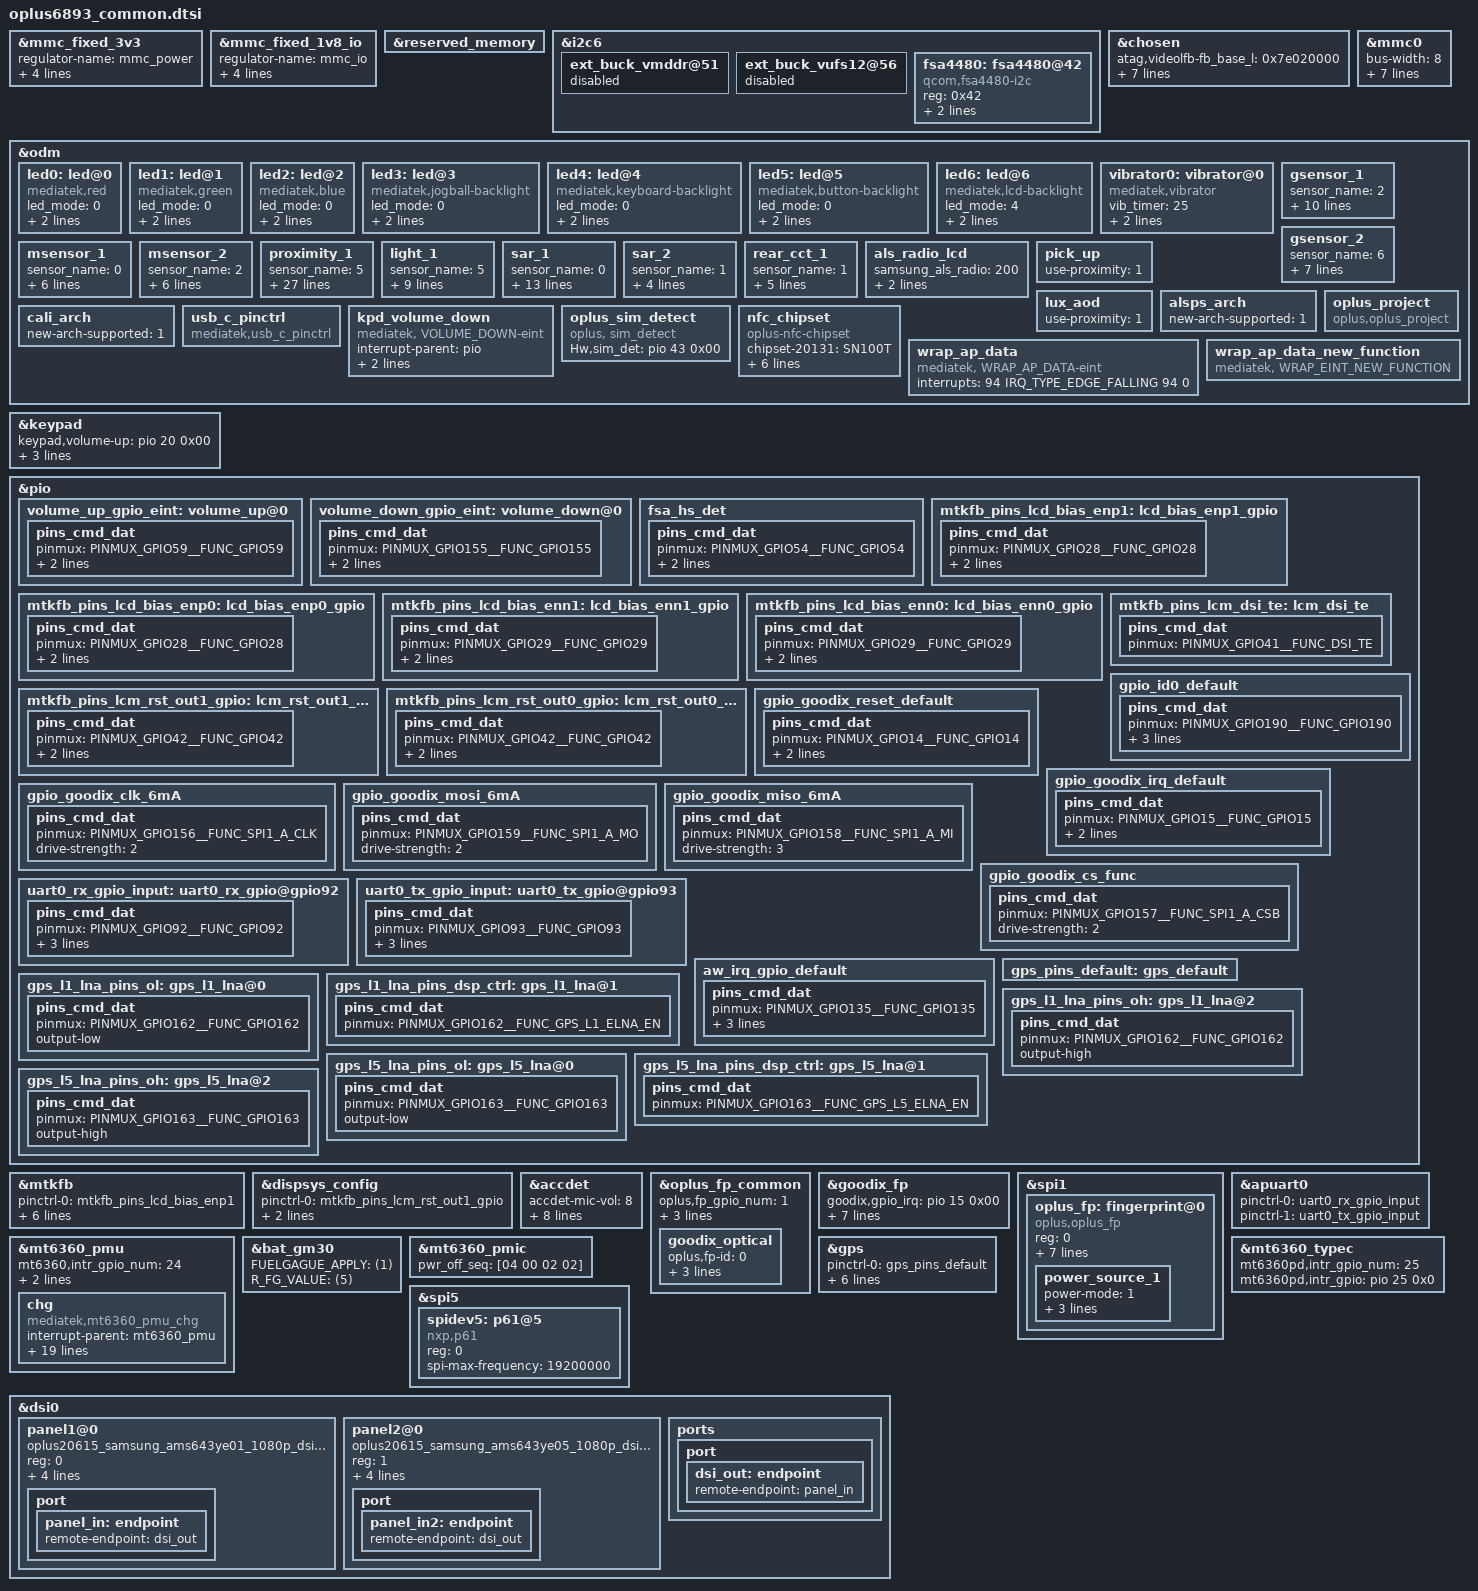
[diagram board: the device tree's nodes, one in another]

&mmc_fixed_3v3 {
	status = "okay";
	regulator-name = "mmc_power";
	regulator-min-microvolt = <3300000>;
	regulator-max-microvolt = <3300000>;
	enable-active-high;
	regulator-always-on;
};

&mmc_fixed_1v8_io {
	status = "okay";
	regulator-name = "mmc_io";
	regulator-min-microvolt = <1800000>;
	regulator-max-microvolt = <1800000>;
	enable-active-high;
	regulator-always-on;
};

&reserved_memory {
};

&i2c6 {

	ext_buck_vmddr@51 {
		status = "disabled";
	};

	ext_buck_vufs12@56 {
		status = "disabled";
	};
 };

/* chosen */
&chosen {

	atag,videolfb-fb_base_l = <0x7e020000>;
	atag,videolfb-fb_base_h = <0x0>;
	atag,videolfb-islcmfound = <1>;
	atag,videolfb-islcm_inited = <0>;
	atag,videolfb-fps= <6000>;
	atag,videolfb-vramSize= <0x1be0000>;
	atag,videolfb-lcmname=
		"nt35595_fhd_dsi_cmd_truly_nt50358_drv";
};

&mmc0 {
	status = "okay";
	/* pinctrl-names = "default", "state_uhs"; */
	/* pinctrl-0 = <&mmc0_pins_default>; */
	/* pinctrl-1 = <&mmc0_pins_uhs>; */
	bus-width = <8>;
	max-frequency = <5000000>;
	cap-mmc-highspeed;
	no-sdio;
	no-sd;
	vmmc-supply = <&mmc_fixed_3v3>;
	vqmmc-supply = <&mmc_fixed_1v8_io>;
	non-removable;
};

&odm {
	led0:led@0 {
		compatible = "mediatek,red";
		led_mode = <0>;
		data = <1>;
		pwm_config = <0 0 0 0 0>;
	};
	led1:led@1 {
		compatible = "mediatek,green";
		led_mode = <0>;
		data = <1>;
		pwm_config = <0 0 0 0 0>;
	};
	led2:led@2 {
		compatible = "mediatek,blue";
		led_mode = <0>;
		data = <1>;
		pwm_config = <0 0 0 0 0>;
	};
	led3:led@3 {
		compatible = "mediatek,jogball-backlight";
		led_mode = <0>;
		data = <1>;
		pwm_config = <0 0 0 0 0>;
	};
	led4:led@4 {
		compatible = "mediatek,keyboard-backlight";
		led_mode = <0>;
		data = <1>;
		pwm_config = <0 0 0 0 0>;
	};
	led5:led@5 {
		compatible = "mediatek,button-backlight";
		led_mode = <0>;
		data = <1>;
		pwm_config = <0 0 0 0 0>;
	};
	led6:led@6 {
		compatible = "mediatek,lcd-backlight";
		led_mode = <4>;
		data = <1>;
		pwm_config = <0 1 0 0 0>;
	};
	vibrator0:vibrator@0 {
		compatible = "mediatek,vibrator";
		vib_timer = <25>;
		vib_limit = <9>;
		vib_vol= <9>;
	};
/* sensor start */
	/*
	enum {
		LIS3DH,
		LSM6DS3,
		BMI160,
		LIS2HH12,
		LSM6DSM,
		BMI2XY,
		LSM6DSO,
	};
	*/
	gsensor_1: gsensor_1 {
		status = "okay";
		sensor_name = <2>;//BMI160
		device_name = "bmi160";
		i2c_num = <2>;
		i2c_addr = <0>;
		direction = <7>;
		eint_num = <3>;
		step_count_7_en = <1>;
		config_miso = <1>;
		correct_y_bias = <1>;
		gyro_cali_version= <2>;
		acc_cali_range= <250 250 250>; //250mg
	};
	gsensor_2: gsensor_2 {
		status = "okay";
		sensor_name = <6>;//LSM6DSO
		device_name = "lsm6dso";
		i2c_num = <2>;
		i2c_addr = <0>;
		direction = <7>;
		eint_num = <3>;
		gyro_cali_version= <2>;
		acc_cali_range= <200 200 200>; //250mg
	};
	/*
	enum {
		AKM09911,
		MMC3530,
		MMC5603,
		MXG4300,
	};
	*/
	msensor_1: msensor_1 {
		status = "okay";
		sensor_name = <0>;//AKM09911
		i2c_num = <0>;
		i2c_addr = <12>;
		direction = <1>;
		eint_num = <0>;
		soft-mag-parameter = <11168 0 285 1 86 1 218 1 9025 0 78 1 263 1 31 0 10658 0>;
	};
	msensor_2: msensor_2 {
		status = "okay";
		sensor_name = <2>;//MMC5603
		i2c_num = <0>;
		i2c_addr = <48>;
		direction = <3>;
		eint_num = <0>;
		soft-mag-parameter = <10343 0 259 0 154 0 259 0 9091 0 49 0 154 0 49 0 10646 0>;
	};
	/*
	enum {
		TMD2725,
		APSD9922,
		STK3335,
		STK3331,
		STK2232,
		TCS3701,
		STK32600,
	};
	*/
	proximity_1: proximity_1 {
		status = "okay";
		sensor_name = <5>;//TCS3701
		i2c_num = <0>;
		i2c_addr = <57>;
		direction = <4>;
		eint_num = <4>;
		low_step = <300>;
		high_step = <400>;
		low_limit = <400>;
		high_limit = <600>;
		dirty_low_step = <100>;
		dirty_high_step = <150>;
		ps_dirty_limit = <1022>;
		ps_ir_limit = <500>;
		ps_adjust_min = <0>;
		ps_adjust_max = <600>;
		sampling_count = <5>;
		step_max = <400>;
		step_min = <110>;
		step_div = <1500>;
		anti_shake_delta = <80>;
		dynamic_cali_max = <1023>;
		raw2offset_radio = <31200>;
		offset_max = <250>;
		offset_range_min = <255>;
		offset_range_max = <255>;
		force_cali_limit = <2000>;
		cali_jitter_limit = <30>;
		cal_offset_margin = <120>;
	};
	light_1: light_1 {
		status = "okay";
		sensor_name = <5>;//TCS3701
		i2c_num = <0>;
		i2c_addr = <57>;
		direction = <4>;
		eint_num = <4>;
		als_ratio = <94>;
		als_buffer_length =<10>;
		lcd_type = <2>;
		use_lb_algo = <1>;
		device_name = "tcs3701";
	};
	/*
	enum {
		SX933x,
		SX933xs,
	};
	*/
	sar_1: sar_1 {
		status = "okay";
		sensor_name = <0>;//SX933x
		i2c_num = <0>;
		i2c_addr = <40>;
		direction = <4>;
		eint_num = <13>;
		channel_num = <2>;
		channel_0_min = <0>;
		channel_0_max = <70000>;
		channel_1_min = <0>;
		channel_1_max = <70000>;
		channel_2_min = <0>;
		channel_2_max = <70000>;
		channel_3_min = <0>;
		channel_3_max = <70000>;
	};

	sar_2: sar_2 {
		status = "okay";
		sensor_name = <1>;//SX933xs
		i2c_num = <0>;
		i2c_addr = <44>;
		direction = <4>;
		eint_num = <13>;
	};

	/*
	enum {
		STK37600,
		MN29005,
		TCS3408,
	};
	*/
	rear_cct_1: rear_cct_1 {
		status = "okay";
		sensor_name = <1>;//MN29005
		i2c_num = <1>;
		i2c_addr = <0x49>;
		direction = <0>;
		eint_num = <0>;
		available_sensor = <0>; // bit 0: rear als, bit 1: rear cct, bit 2: rear flicker
	};

	als_radio_lcd:als_radio_lcd {
		status = "okay";
		samsung_als_radio = <200>;
		boe_als_radio = <150>;
		tianma_als_radio = <150>;
	};
	pick_up: pick_up {
		status = "okay";
		use-proximity = <1>;
	};
	lux_aod: lux_aod {
		status = "okay";
		use-proximity = <1>;
	};
	alsps_arch: alsps_arch {
		status = "okay";
		new-arch-supported = <1>;
	};
	cali_arch: cali_arch {
		status = "okay";
		new-arch-supported = <1>;
	};
/* sensor end */
	usb_c_pinctrl:usb_c_pinctrl {
		compatible = "mediatek,usb_c_pinctrl";
	};
/*OPLUS_FEATURE_TP_BASIC oplus project start */
	oplus_project:oplus_project {
		compatible = "oplus,oplus_project";
	};
/*endif*/
//#ifdef OPLUS_FEATURE_TP_BASIC
        kpd_volume_down:kpd_volume_down {
                compatible = "mediatek, VOLUME_DOWN-eint";
                interrupt-parent = <&pio>;
                interrupts = <155 IRQ_TYPE_EDGE_FALLING 155 0>;
                debounce = <32000>;
                status = "okay";
        };

//#endif OPLUS_FEATURE_TP_BASIC

//#ifdef OPLUS_FEATURE_TP_BASIC
    oplus_sim_detect {
        compatible = "oplus, sim_detect";
        Hw,sim_det = <&pio 43 0x00>;
    };
//#endif /* OPLUS_FEATURE_TP_BASIC */

    nfc_chipset:nfc_chipset {
        compatible = "oplus-nfc-chipset";
        chipset-20131 = "SN100T";
        chipset-20133 = "SN100T";
        chipset-20255 = "SN100T";
        chipset-20615 = "SN100T";
        chipset-20817 = "SN100T";
        chipset-20827 = "SN100T";
        chipset-20831 = "SN100T";
    };
//#endif /* OPLUS_FEATURE_NFC_CONSOFT */

};
//#ifdef OPLUS_FEATURE_TP_BASIC
&keypad {
        keypad,volume-up        = <&pio 20 0x00>;
        keypad,volume-down      = <&pio 155 0x00>;
        pinctrl-names = "volume_up_as_int", "volume_down_as_int";
        pinctrl-0 = <&volume_up_gpio_eint>;
        pinctrl-1 = <&volume_down_gpio_eint>;
        status = "okay";
};

&pio {
        volume_up_gpio_eint:volume_up@0{
                pins_cmd_dat {
                        pinmux = <PINMUX_GPIO59__FUNC_GPIO59>;
                        slew-rate = <0>;  /*direction 0:in, 1:out*/
                        input-enable;
                };
        };

        volume_down_gpio_eint:volume_down@0{
                pins_cmd_dat {
                        pinmux = <PINMUX_GPIO155__FUNC_GPIO155>;
                        slew-rate = <0>;  /*direction 0:in, 1:out*/
                        input-enable;
                };
        };
};
//#endif OPLUS_FEATURE_TP_BASIC

//#ifdef OPLUS_ARCH_EXTENDS
&i2c6 {
	fsa4480: fsa4480@42 {
		compatible = "qcom,fsa4480-i2c";
		reg = <0x42>;
		pinctrl-names = "default";
		pinctrl-0 = <&fsa_hs_det>;
		fsa4480,hs-det-gpio = <&pio 54 0>;
	};
};

&pio {
	fsa_hs_det: fsa_hs_det {
		pins_cmd_dat {
			pinmux = <PINMUX_GPIO54__FUNC_GPIO54>;
			slew-rate = <1>;  /*direction 0:in, 1:out*/
			output-high;
		};
	};
	/*
	aud_gpio_i2s0_on: aud_gpio_i2s0_on {
		pins_cmd1_dat {
			pinmux = <PINMUX_GPIO34__FUNC_I2S3_DI>;
		};
	};*/
};
//#endif /*OPLUS_ARCH_EXTENDS*/

/* DISPSYS GPIO standardization */
&pio {
	mtkfb_pins_lcd_bias_enp1: lcd_bias_enp1_gpio {
		pins_cmd_dat {
			pinmux = <PINMUX_GPIO28__FUNC_GPIO28>;
			slew-rate = <1>;
			output-high;
		};
	};

	mtkfb_pins_lcd_bias_enp0: lcd_bias_enp0_gpio {
		pins_cmd_dat {
			pinmux = <PINMUX_GPIO28__FUNC_GPIO28>;
			slew-rate = <1>;
			output-low;
		};
	};

	mtkfb_pins_lcd_bias_enn1: lcd_bias_enn1_gpio {
		pins_cmd_dat {
			pinmux = <PINMUX_GPIO29__FUNC_GPIO29>;
			slew-rate = <1>;
			output-high;
		};
	};

	mtkfb_pins_lcd_bias_enn0: lcd_bias_enn0_gpio {
		pins_cmd_dat {
			pinmux = <PINMUX_GPIO29__FUNC_GPIO29>;
			slew-rate = <1>;
			output-low;
		};
	};

	mtkfb_pins_lcm_rst_out1_gpio: lcm_rst_out1_gpio {
		pins_cmd_dat {
			pinmux = <PINMUX_GPIO42__FUNC_GPIO42>;
			slew-rate = <1>;
			output-high;
		};
	};

	mtkfb_pins_lcm_rst_out0_gpio: lcm_rst_out0_gpio {
		pins_cmd_dat {
			pinmux = <PINMUX_GPIO42__FUNC_GPIO42>;
			slew-rate = <1>;
			output-low;
		};
	};

	mtkfb_pins_lcm_dsi_te: lcm_dsi_te {
		pins_cmd_dat {
			pinmux = <PINMUX_GPIO41__FUNC_DSI_TE>;
		};
	};
};

&mtkfb {
	pinctrl-names = "lcd_bias_enp1_gpio", "lcd_bias_enp0_gpio",
		"lcd_bias_enn1_gpio", "lcd_bias_enn0_gpio",
		"lcm_rst_out1_gpio", "lcm_rst_out0_gpio",
		"mode_te_te";
	pinctrl-0 = <&mtkfb_pins_lcd_bias_enp1>;
	pinctrl-1 = <&mtkfb_pins_lcd_bias_enp0>;
	pinctrl-2 = <&mtkfb_pins_lcd_bias_enn1>;
	pinctrl-3 = <&mtkfb_pins_lcd_bias_enn0>;
	pinctrl-4 = <&mtkfb_pins_lcm_rst_out1_gpio>;
	pinctrl-5 = <&mtkfb_pins_lcm_rst_out0_gpio>;
	pinctrl-6 = <&mtkfb_pins_lcm_dsi_te>;
	status = "okay";
};

&dispsys_config {
	pinctrl-names =
		"lcm_rst_out1_gpio", "lcm_rst_out0_gpio",
		"mode_te_te";
	pinctrl-0 = <&mtkfb_pins_lcm_rst_out1_gpio>;
	pinctrl-1 = <&mtkfb_pins_lcm_rst_out0_gpio>;
	pinctrl-2 = <&mtkfb_pins_lcm_dsi_te>;
	status = "okay";
};
/* DISPSYS GPIO standardization end */

/* accdet start */
&accdet {
	/* accdet micbias voltage: 0x09:2.85v 0x08:2.8v 0x07,
	 * 2.7v;0x05,2.5v;0x02,1.9v
	 */
	accdet-mic-vol = <8>;
	/* accdet pwm_width, pwm_thresh, fall_delay, rise_delay
	 * debounce0, debounce1, debounce3, debounce4
	 * eint pwm_width, eint pwm_thresh
	 * eint deb(debounce0, debounce1, debounce2, debounce3), inv_debounce
	 */
	headset-mode-setting = <0x500 0x500 1 0x1f0
				0x800 0x800 0x20 0x44
				0x4 0x1
				0x5 0x3 0x3 0x5 0xe>;
	accdet-plugout-debounce = <1>;
	/*1:ACC mode, 2:low cost without in bias, 6:low cost with in bias*/
	accdet-mic-mode = <2>;
	/*0--MD_MAX--UP_MAX--DW_MAX*/
	headset-three-key-threshold = <0 82 170 306>;
	headset-three-key-threshold-CDD = <0 121 192 600>;
	/*0--MD_MAX--VOICE_MAX--UP_MAX--DW_MAX*/
	headset-four-key-threshold = <0 58 121 192 400>;

	/* select VTH to 2v and 500k, use internal resitance */
	eint_use_ext_res = <0>;
	status = "okay";
};
/* accdet end */

/* IRTX GPIO Start */
/*
&irtx_pwm {
	pinctrl-names = "irtx_gpio_led_default", "irtx_gpio_led_set";
	pinctrl-0 = <&irtx_gpio_led_default>;
	pinctrl-1 = <&irtx_gpio_led_set>;
	status = "okay";
};
*/
&pio {
	/* IRTX GPIO Settings -Start */
	/* default: GPIO0, output, high */
	/*
	irtx_gpio_led_default:irtx_gpio_led_def@gpio127 {
		pins_cmd_dat {
			pinmux = <PINMUX_GPIO127__FUNC_GPIO127>;
			slew-rate = <1>;
			bias-disable;
			output-low;
			input-schmitt-enable = <0>;
		};
	};

	irtx_gpio_led_set:irtx_gpio_led_set@gpio127 {
		pins_cmd_dat {
			pinmux = <PINMUX_GPIO127__FUNC_PWM_3>;
			slew-rate = <1>;
			output-high;
		};
	};*/
}; /* IRTX GPIO Settings -End */

/* FINGERPRINT start */
&oplus_fp_common {
    oplus,fp_gpio_num = <1>;
    oplus,fp_gpio = <190>;
    oplus,fp_gpio_id = <&pio 190 0x0>;
    pinctrl-names = "default";
    pinctrl-0 = <&gpio_id0_default>;
    goodix_optical {
        oplus,fp-id = <0>; // fp id mapping table
        vendor-chip = <11>; // please refer to the struct fp_vendor_t in oplus_fp_commmon.n
        eng-menu = "-1,-1"; // represents SNR, inclination test item in engineer menu, and 0/1 means off/on
        chip-name = "G_OPTICAL_G3S";  // /proc/fp_id, will be displayed in engineer menu
	};
};

&pio{
	gpio_id0_default: gpio_id0_default {
		pins_cmd_dat {
			pinmux = <PINMUX_GPIO190__FUNC_GPIO190>;
			slew-rate = <0>;
			bias-pull-up = <00>;
			input-enable;
		};
	};
};

&goodix_fp {
	goodix,gpio_irq = <&pio 15 0x00>;
	goodix,gpio_reset = <&pio 14 0x00>;
	goodix,gpio_cs = <&pio 157 0x00>;
	pinctrl-names = "default", "gf_spi_drive_6mA", "gf_cs_func";
	pinctrl-0 = <&gpio_goodix_irq_default>, <&gpio_goodix_reset_default>;
	pinctrl-1 = <&gpio_goodix_clk_6mA>, <&gpio_goodix_mosi_6mA>, <&gpio_goodix_miso_6mA>;
	pinctrl-2 = <&gpio_goodix_cs_func>;
	status = "okay";
};

&spi1 {
#address-cells = <1>;
#size-cells = <0>;
status = "okay";
oplus_fp: fingerprint@0 {
		 compatible = "oplus,oplus_fp";
		 reg = <0>;
		 spi-max-frequency = <8000000>;
		 spi-id = <1>;
		 spi-irq = <15>;
		 spi-reg = <11010000>;
		 dvdd-supply = <&mt_pmic_vmch_ldo_reg>;
		 dvdd-config = <3300000 3300000 150000>;
		 power-num = <1>;
		 status = "okay";
		 power_source_1 {
			 power-mode = <1>;
			 power-name = "dvdd";
			 power-config = "dvdd-config";
			 delay-time = <0>;
		 };
	 };
};
// 1 = ldo power, refer to oplus_fp_common.h
&pio{
gpio_goodix_reset_default: gpio_goodix_reset_default {
				   pins_cmd_dat {
					   pinmux = <PINMUX_GPIO14__FUNC_GPIO14>;
					   slew-rate = <1>;
					   output-low;
				   };
			   };
gpio_goodix_irq_default: gpio_goodix_irq_default {
				 pins_cmd_dat {
					 pinmux = <PINMUX_GPIO15__FUNC_GPIO15>;
					 slew-rate = <0>;
					 bias-pull-down;
				 };
			 };
gpio_goodix_clk_6mA: gpio_goodix_clk_6mA {
			     pins_cmd_dat {
				      pinmux = <PINMUX_GPIO156__FUNC_SPI1_A_CLK>;
				      drive-strength = <2>;
			     };
		     };
gpio_goodix_mosi_6mA: gpio_goodix_mosi_6mA {
			      pins_cmd_dat {
				      pinmux = <PINMUX_GPIO159__FUNC_SPI1_A_MO>;
				      drive-strength = <2>;
			      };
		      };
gpio_goodix_miso_6mA: gpio_goodix_miso_6mA {
			      pins_cmd_dat {
				      pinmux = <PINMUX_GPIO158__FUNC_SPI1_A_MI>;
				      drive-strength = <3>;
			      };
		      };
gpio_goodix_cs_func: gpio_goodix_cs_func {
			     pins_cmd_dat {
				     pinmux = <PINMUX_GPIO157__FUNC_SPI1_A_CSB>;
				     drive-strength = <2>;
			     };
		     };
};
//#endif
/* FINGERPRINT end */

&apuart0 {
	pinctrl-names = "uart0_rx_gpio",
			"uart0_tx_gpio";
	pinctrl-0 = <&uart0_rx_gpio_input>;
	pinctrl-1 = <&uart0_tx_gpio_input>;
	status = "okay";
};

&pio {
	uart0_rx_gpio_input:uart0_rx_gpio@gpio92 {
		pins_cmd_dat {
			pinmux = <PINMUX_GPIO92__FUNC_GPIO92>;
			input-enable;
			slew-rate = <0>;
			bias-disable;
		};
	};
	uart0_tx_gpio_input:uart0_tx_gpio@gpio93 {
		pins_cmd_dat {
			pinmux = <PINMUX_GPIO93__FUNC_GPIO93>;
			input-enable;
			slew-rate = <0>;
			bias-disable;
		};
	};
};

&mt6360_pmu {
	chg {
		compatible = "mediatek,mt6360_pmu_chg";
		interrupt-parent = <&mt6360_pmu>;
		interrupts = <4 0>, <6 0>, <7 0>, <9 0>,
				<12 0>, <13 0>, <14 0>, <15 0>,
				<27 0>, <29 0>, <30 0>, <32 0>,
				<35 0>, <40 0>, <48 0>, <60 0>,
				<53 0>;
		interrupt-names = "chg_treg_evt", "chg_mivr_evt",
				"pwr_rdy_evt", "chg_batsysuv_evt",
				"chg_vsysuv_evt", "chg_vsysov_evt",
				"chg_vbatov_evt", "chg_vbusov_evt",
				"chg_tmri", "chg_adpbadi",
				"chg_rvpi",  "chg_aiccmeasl",
				"wdtmri", "pumpx_donei",
				"attachi", "chrdet_ext_evt",
				"hvdcp_det";
		io-channels = <&adc 0>, <&adc 1>, <&adc 3>, <&adc 4>,
				<&adc 5>, <&adc 6>, <&adc 8>, <&adc 10>;
		io-channel-names = "USBID", "VBUSDIV5", "VSYS", "VBAT",
				"IBUS", "IBAT", "TEMP_JC", "TS";
		chg_name = "primary_chg";
		ichg = <2000000>;               /* uA */
		aicr = <500000>;                /* uA */
		mivr = <4400000>;               /* uV */
		cv = <4350000>;                 /* uA */
		ieoc = <150000>;                /* uA */
		safety_timer = <12>;            /* hour */
		ircmp_resistor = <25000>;       /* uohm */
		ircmp_vclamp = <32000>;         /* uV */
		en_te = <1>;
		en_wdt = <1>;
		aicc_once = <1>;
		post_aicc = <1>;
		batoc_notify = <0>;
	};
};

&bat_gm30 {
	FUELGAGUE_APPLY = <(1)>;
	R_FG_VALUE = <(5)>;
};


&pio{
	aw_irq_gpio_default: aw_irq_gpio_default {		//check
		pins_cmd_dat {
			pinmux = <PINMUX_GPIO135__FUNC_GPIO135>;
			input-enable;
			slew-rate = <0>;
			bias-pull-up;
		};
	};

};

&odm {
	wrap_ap_data:wrap_ap_data {
		compatible = "mediatek, WRAP_AP_DATA-eint";
		interrupts = <94 IRQ_TYPE_EDGE_FALLING 94 0>;
	};
	wrap_ap_data_new_function:wrap_ap_data_new_function {
		compatible = "mediatek, WRAP_EINT_NEW_FUNCTION";
	};
};

&mt6360_pmu {
	mt6360,intr_gpio_num = <24>; /* direct defined GPIO num */
	mt6360,intr_gpio = <&pio 24 0x0>;
	disable_lpsd = <1>;
};

&mt6360_pmic {
	pwr_off_seq = [04 00 02 02];
};

&mt6360_typec {
	mt6360pd,intr_gpio_num = <25>; /* direct defined GPIO num */
	mt6360pd,intr_gpio = <&pio 25 0x0>;
};

/* USB SWITCH GPIO start */
//#ifdef OPLUS_ARCH_EXTENDS
//#endif
/*
&pio {
	usb_default: usb_default {
	};

	gpio_redriver_c1_init: c1_init {
		pins_cmd_dat {
			pinmux = <PINMUX_GPIO113__FUNC_GPIO113>;
			slew-rate = <1>;
			output-low;
		};
	};

	gpio_redriver_c1_low: c1_low {
		pins_cmd_dat {
			pinmux = <PINMUX_GPIO113__FUNC_GPIO113>;
			slew-rate = <1>;
			output-low;
		};
	};

	gpio_redriver_c1_hiz: c1_highz {
		pins_cmd_dat {
			pinmux = <PINMUX_GPIO113__FUNC_GPIO113>;
			slew-rate= <0>;
			bias-disable;
		};
	};

	gpio_redriver_c1_high: c1_high {
		pins_cmd_dat {
			pinmux = <PINMUX_GPIO113__FUNC_GPIO113>;
			slew-rate = <1>;
			output-high;
		};
	};

	gpio_redriver_c2_init: c2_init {
		pins_cmd_dat {
			pinmux = <PINMUX_GPIO112__FUNC_GPIO112>;
			slew-rate = <1>;
			output-low;
		};
	};

	gpio_redriver_c2_low: c2_low {
		pins_cmd_dat {
			pinmux = <PINMUX_GPIO112__FUNC_GPIO112>;
			slew-rate = <1>;
			output-low;
		};
	};

	gpio_redriver_c2_hiz: c2_highz {
		pins_cmd_dat {
			pinmux = <PINMUX_GPIO112__FUNC_GPIO112>;
			slew-rate= <0>;
			bias-disable;
		};
	};

	gpio_redriver_c2_high: c2_high {
		pins_cmd_dat {
			pinmux = <PINMUX_GPIO112__FUNC_GPIO112>;
			slew-rate = <1>;
			output-high;
		};
	};

	gpio_u3_switch_sel1: u3_sw_sel1 {
		pins_cmd_dat {
			pinmux = <PINMUX_GPIO111__FUNC_GPIO111>;
			slew-rate = <1>;
			output-low;
		};
	};

	gpio_u3_switch_sel2: u3_sw_sel2 {
		pins_cmd_dat {
			pinmux = <PINMUX_GPIO111__FUNC_GPIO111>;
			slew-rate = <1>;
			output-high;
		};
	};

	gpio_u3_switch_enable: u3_sw_en {
	};

	gpio_u3_switch_disable: u3_sw_dis {
	};
};

&usb_c_pinctrl {
	pinctrl-names = "usb_default",
		"redrv_c1_init",
		"redrv_c1_low",
		"redrv_c1_hiz",
		"redrv_c1_high",
		"redrv_c2_init",
		"redrv_c2_low",
		"redrv_c2_hiz",
		"redrv_c2_high",
		"switch_sel1",
		"switch_sel2",
		"switch_enable",
		"switch_disable";

	pinctrl-0 = <&usb_default>;
	pinctrl-1 = <&gpio_redriver_c1_init>;
	pinctrl-2 = <&gpio_redriver_c1_low>;
	pinctrl-3 = <&gpio_redriver_c1_hiz>;
	pinctrl-4 = <&gpio_redriver_c1_high>;
	pinctrl-5 = <&gpio_redriver_c2_init>;
	pinctrl-6 = <&gpio_redriver_c2_low>;
	pinctrl-7 = <&gpio_redriver_c2_hiz>;
	pinctrl-8 = <&gpio_redriver_c2_high>;
	pinctrl-9 = <&gpio_u3_switch_sel1>;
	pinctrl-10 = <&gpio_u3_switch_sel2>;
	pinctrl-11 = <&gpio_u3_switch_enable>;
	pinctrl-12 = <&gpio_u3_switch_disable>;
	status = "okay";

	usb_switch-data {
		en_pin_num = <0>;
		en_pin_val = <0>;
		sel_pin_num = <111>;
		sel_pin_val = <1>;
		c1_pin_num = <113>;
		c1_pin_val = <2>;
		c2_pin_num = <112>;
		c2_pin_val = <1>;
	};
};
*/
/* USB SWITCH GPIO end */

//#ifdef OPLUS_FEATURE_NFC_BRINGUP
&spi5 {
       status = "okay";
       #address-cells = <1>;
       #size-cells = <0>;
       spidev5: p61@5 {
       compatible = "nxp,p61";
       reg = <0>;
       spi-max-frequency = <19200000>;
       };
};
//#endif /* OPLUS_FEATURE_NFC_BRINGUP */

/* GPS GPIO standardization start */
&pio {
	gps_pins_default: gps_default {
	};

	gps_l1_lna_pins_ol: gps_l1_lna@0 {
		pins_cmd_dat {
			pinmux = <PINMUX_GPIO162__FUNC_GPIO162>;
			output-low;
		};
	};
	gps_l1_lna_pins_dsp_ctrl: gps_l1_lna@1 {
		pins_cmd_dat {
			pinmux = <PINMUX_GPIO162__FUNC_GPS_L1_ELNA_EN>;
		};
	};
	gps_l1_lna_pins_oh: gps_l1_lna@2 {
		pins_cmd_dat {
			pinmux = <PINMUX_GPIO162__FUNC_GPIO162>;
			output-high;
		};
	};

	gps_l5_lna_pins_ol: gps_l5_lna@0 {
		pins_cmd_dat {
			pinmux = <PINMUX_GPIO163__FUNC_GPIO163>;
			output-low;
		};
	};
	gps_l5_lna_pins_dsp_ctrl: gps_l5_lna@1 {
		pins_cmd_dat {
			pinmux = <PINMUX_GPIO163__FUNC_GPS_L5_ELNA_EN>;
		};
	};
	gps_l5_lna_pins_oh: gps_l5_lna@2 {
		pins_cmd_dat {
			pinmux = <PINMUX_GPIO163__FUNC_GPIO163>;
			output-high;
		};
	};
};

&gps {
	pinctrl-names = "default",
		"gps_l1_lna_disable",
		"gps_l1_lna_dsp_ctrl",
		"gps_l1_lna_enable",
		"gps_l5_lna_disable",
		"gps_l5_lna_dsp_ctrl",
		"gps_l5_lna_enable";
	pinctrl-0 = <&gps_pins_default>;
	pinctrl-1 = <&gps_l1_lna_pins_ol>;
	pinctrl-2 = <&gps_l1_lna_pins_dsp_ctrl>;
	pinctrl-3 = <&gps_l1_lna_pins_oh>;
	pinctrl-4 = <&gps_l5_lna_pins_ol>;
	pinctrl-5 = <&gps_l5_lna_pins_dsp_ctrl>;
	pinctrl-6 = <&gps_l5_lna_pins_oh>;
	status = "okay";
};
/* GPS GPIO standardization end */

&dsi0 {
	status = "okay";
	#address-cells = <1>;
	#size-cells = <0>;
	panel1@0 {
		compatible = "oplus20615_samsung_ams643ye01_1080p_dsi_cmd";
		reg = <0>;
		pm-enable-gpios = <&pio 41 0>;
		reset-gpios = <&pio 42 0>;
		bias-gpios = <&pio 29 0>;
		ldo3-supply = <&mt_pmic_vmc_ldo_reg>;
		pinctrl-names = "default";
		port {
			panel_in: endpoint {
				remote-endpoint = <&dsi_out>;
			};
		};
	};
	panel2@0 {
		compatible = "oplus20615_samsung_ams643ye05_1080p_dsi_cmd";
		reg = <1>;
		pm-enable-gpios = <&pio 41 0>;
		reset-gpios = <&pio 42 0>;
		bias-gpios = <&pio 29 0>;
		ldo3-supply = <&mt_pmic_vmc_ldo_reg>;
		pinctrl-names = "default";
		port {
			panel_in2: endpoint {
				remote-endpoint = <&dsi_out>;
			};
		};
	};
	ports {
		port {
			dsi_out: endpoint {
				remote-endpoint = <&panel_in>;
			};
		};
	};
};
